VERSION ""

NS_ :

BS_:

BU_: Other ECU
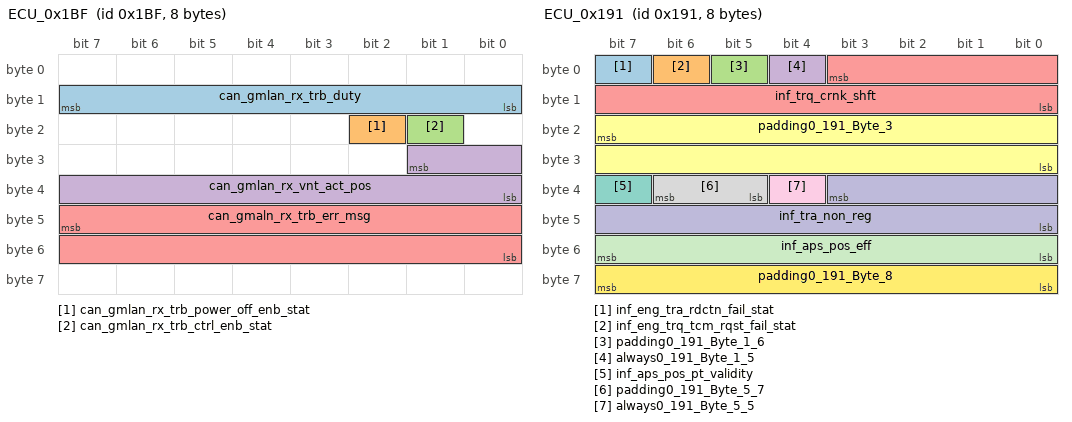
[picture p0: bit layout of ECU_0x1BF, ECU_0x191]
BO_ 447 ECU_0x1BF: 8 Other
 SG_ can_gmlan_rx_trb_duty : 15|8@0+ (1,0) [-100|100] "%"  ECU
 SG_ can_gmlan_rx_trb_power_off_enb_stat : 18|1@0+ (1,0) [0|1] "-"  ECU
 SG_ can_gmlan_rx_trb_ctrl_enb_stat : 17|1@0+ (1,0) [0|1] "-"  ECU
 SG_ can_gmlan_rx_vnt_act_pos : 25|10@0+ (0.1,0) [0|100] "%"  ECU
 SG_ can_gmaln_rx_trb_err_msg : 47|16@0+ (1,0) [0|65535] "-"  ECU

BO_ 401 ECU_0x191: 8 ECU
 SG_ inf_eng_tra_rdctn_fail_stat : 7|1@0+ (1,0) [0|1] "-"  Other
 SG_ inf_eng_trq_tcm_rqst_fail_stat : 6|1@0+ (1,0) [0|1] "-"  Other
 SG_ padding0_191_Byte_1_6 : 5|1@0+ (1,0) [0|0] "-"  Other
 SG_ always0_191_Byte_1_5 : 4|1@0+ (1,0) [0|1] "-"  Other
 SG_ inf_trq_crnk_shft : 3|12@0+ (0.5,-848) [-848|1199.5] "Nm"  Other
 SG_ padding0_191_Byte_3 : 23|16@0+ (1,0) [0|0] "-"  Other
 SG_ inf_aps_pos_pt_validity : 39|1@0+ (1,0) [0|1] "-"  Other
 SG_ padding0_191_Byte_5_7 : 38|2@0+ (1,0) [0|0] "-"  Other
 SG_ always0_191_Byte_5_5 : 36|1@0+ (1,0) [0|1] "-"  Other
 SG_ inf_tra_non_reg : 35|12@0+ (0.5,-848) [-848|1199.5] "Nm"  Other
 SG_ inf_aps_pos_eff : 55|8@0+ (0.39215686274509803,0) [0|100] "%"  Other
 SG_ padding0_191_Byte_8 : 63|8@0+ (1,0) [0|0] "-"  Other

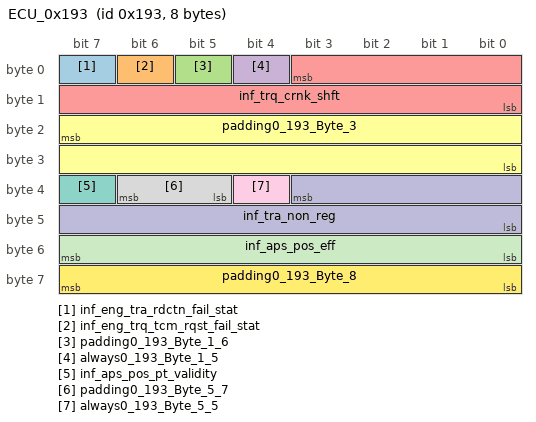
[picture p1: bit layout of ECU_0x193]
BO_ 403 ECU_0x193: 8 ECU
 SG_ inf_eng_tra_rdctn_fail_stat : 7|1@0+ (1,0) [0|1] "-"  Other
 SG_ inf_eng_trq_tcm_rqst_fail_stat : 6|1@0+ (1,0) [0|1] "-"  Other
 SG_ padding0_193_Byte_1_6 : 5|1@0+ (1,0) [0|0] "-"  Other
 SG_ always0_193_Byte_1_5 : 4|1@0+ (1,0) [0|1] "-"  Other
 SG_ inf_trq_crnk_shft : 3|12@0+ (0.5,-848) [-848|1199.5] "Nm"  Other
 SG_ padding0_193_Byte_3 : 23|16@0+ (1,0) [0|0] "-"  Other
 SG_ inf_aps_pos_pt_validity : 39|1@0+ (1,0) [0|1] "-"  Other
 SG_ padding0_193_Byte_5_7 : 38|2@0+ (1,0) [0|0] "-"  Other
 SG_ always0_193_Byte_5_5 : 36|1@0+ (1,0) [0|1] "-"  Other
 SG_ inf_tra_non_reg : 35|12@0+ (0.5,-848) [-848|1199.5] "Nm"  Other
 SG_ inf_aps_pos_eff : 55|8@0+ (0.39215686274509803,0) [0|100] "%"  Other
 SG_ padding0_193_Byte_8 : 63|8@0+ (1,0) [0|0] "-"  Other

CM_ BO_ 447 "Turbo Control";
CM_ SG_ 447 can_gmlan_rx_trb_duty "CAN Turbo Duty";
CM_ SG_ 447 can_gmlan_rx_trb_power_off_enb_stat "CAN Turbo Power Off Enable Status";
CM_ SG_ 447 can_gmlan_rx_trb_ctrl_enb_stat "EVGT Turbo Control Enable Status";
CM_ SG_ 447 can_gmlan_rx_vnt_act_pos "CAN Variable Npzzle Turbo Actual Position";
CM_ SG_ 447 can_gmaln_rx_trb_err_msg "CAN Turbo Error Message";
CM_ BO_ 401 "Engine Torque Status";
CM_ SG_ 401 inf_eng_tra_rdctn_fail_stat "Engine Torque Reduction Failed";
CM_ SG_ 401 inf_eng_trq_tcm_rqst_fail_stat "Engine Torque TCM Request Failed";
CM_ SG_ 401 padding0_191_Byte_1_6 "(Not defined)";
CM_ SG_ 401 always0_191_Byte_1_5 "Engine Actual Steady State Torque Validity";
CM_ SG_ 401 inf_trq_crnk_shft "Engine actual steady state torque";
CM_ SG_ 401 padding0_191_Byte_3 "(Not defined)";
CM_ SG_ 401 inf_aps_pos_pt_validity "Accelerator Effective Position Validity";
CM_ SG_ 401 padding0_191_Byte_5_7 "(Not defined)";
CM_ SG_ 401 always0_191_Byte_5_5 "Engine Non-Transmission Regulated Steady State Torque Validity";
CM_ SG_ 401 inf_tra_non_reg "Engine Non-Transmission Regulated Steady State Torque";
CM_ SG_ 401 inf_aps_pos_eff "Accelerator Effective Position";
CM_ SG_ 401 padding0_191_Byte_8 "(Not defined)";
CM_ BO_ 403 "Engine Torque Status";
CM_ SG_ 403 inf_eng_tra_rdctn_fail_stat "Engine Torque Reduction Failed";
CM_ SG_ 403 inf_eng_trq_tcm_rqst_fail_stat "Engine Torque TCM Request Failed";
CM_ SG_ 403 padding0_193_Byte_1_6 "(Not defined)";
CM_ SG_ 403 always0_193_Byte_1_5 "Engine Actual Steady State Torque Validity";
CM_ SG_ 403 inf_trq_crnk_shft "Engine actual steady state torque";
CM_ SG_ 403 padding0_193_Byte_3 "(Not defined)";
CM_ SG_ 403 inf_aps_pos_pt_validity "Accelerator Effective Position Validity";
CM_ SG_ 403 padding0_193_Byte_5_7 "(Not defined)";
CM_ SG_ 403 always0_193_Byte_5_5 "Engine Non-Transmission Regulated Steady State Torque Validity";
CM_ SG_ 403 inf_tra_non_reg "Engine Non-Transmission Regulated Steady State Torque";
CM_ SG_ 403 inf_aps_pos_eff "Accelerator Effective Position";
CM_ SG_ 403 padding0_193_Byte_8 "(Not defined)";

BA_DEF_  "BusType" STRING ;
BA_DEF_ BO_  "GenMsgCycleTime" INT 2 50000;
BA_DEF_ BO_  "GenMsgSendType" ENUM  "cyclic","spontaneous","cyclicIfActive","spontaneousWithDelay","cyclicAndSpontaneous","cyclicAndSpontaneousWithDelay","spontaneousWithRepetition","cyclicIfActiveAndSpontaneousWD";
BA_DEF_DEF_  "BusType" "CAN";
BA_DEF_DEF_  "GenMsgCycleTime" 10;
BA_DEF_DEF_  "GenMsgSendType" "cyclic";
BA_ "GenMsgCycleTime" BO_ 447 15;
